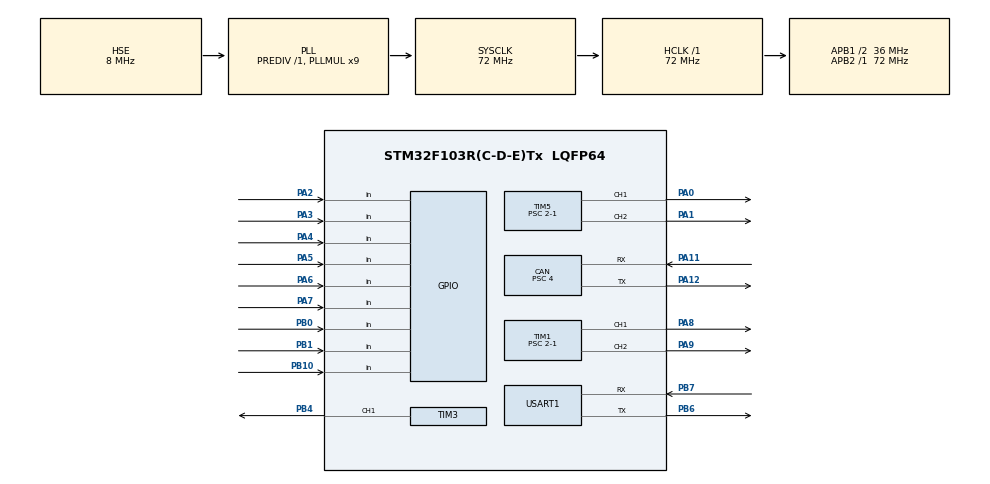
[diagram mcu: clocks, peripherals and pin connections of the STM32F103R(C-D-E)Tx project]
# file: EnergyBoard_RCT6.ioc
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CAN.AWUM=ENABLE
CAN.BS1=CAN_BS1_5TQ
CAN.BS2=CAN_BS2_3TQ
CAN.CalculateBaudRate=1000000
CAN.CalculateTimeBit=1000
CAN.CalculateTimeQuantum=111.11111111111111
CAN.Prescaler=4
CAN.TXFP=ENABLE
Dma.Request0=TIM1_CH1
Dma.Request1=TIM1_CH2
Dma.Request2=TIM3_CH1/TRIG
Dma.Request3=TIM5_CH1
Dma.Request4=TIM5_CH2
Dma.Request5=USART1_TX
Dma.TIM1_CH1.0.Direction=DMA_MEMORY_TO_PERIPH
Dma.TIM1_CH1.0.Instance=DMA1_Channel2
Dma.TIM1_CH1.0.MemDataAlignment=DMA_MDATAALIGN_HALFWORD
Dma.TIM1_CH1.0.MemInc=DMA_MINC_ENABLE
Dma.TIM1_CH1.0.Mode=DMA_NORMAL
Dma.TIM1_CH1.0.PeriphDataAlignment=DMA_PDATAALIGN_HALFWORD
Dma.TIM1_CH1.0.PeriphInc=DMA_PINC_DISABLE
Dma.TIM1_CH1.0.Priority=DMA_PRIORITY_LOW
Dma.TIM1_CH2.1.Direction=DMA_MEMORY_TO_PERIPH
Dma.TIM1_CH2.1.Instance=DMA1_Channel3
Dma.TIM1_CH2.1.MemDataAlignment=DMA_MDATAALIGN_HALFWORD
Dma.TIM1_CH2.1.MemInc=DMA_MINC_ENABLE
Dma.TIM1_CH2.1.Mode=DMA_NORMAL
Dma.TIM1_CH2.1.PeriphDataAlignment=DMA_PDATAALIGN_HALFWORD
Dma.TIM1_CH2.1.PeriphInc=DMA_PINC_DISABLE
Dma.TIM1_CH2.1.Priority=DMA_PRIORITY_LOW
Dma.TIM3_CH1/TRIG.2.Direction=DMA_MEMORY_TO_PERIPH
Dma.TIM3_CH1/TRIG.2.Instance=DMA1_Channel6
Dma.TIM3_CH1/TRIG.2.MemDataAlignment=DMA_MDATAALIGN_HALFWORD
Dma.TIM3_CH1/TRIG.2.MemInc=DMA_MINC_ENABLE
Dma.TIM3_CH1/TRIG.2.Mode=DMA_NORMAL
Dma.TIM3_CH1/TRIG.2.PeriphDataAlignment=DMA_PDATAALIGN_HALFWORD
Dma.TIM3_CH1/TRIG.2.PeriphInc=DMA_PINC_DISABLE
Dma.TIM3_CH1/TRIG.2.Priority=DMA_PRIORITY_LOW
Dma.TIM5_CH1.3.Direction=DMA_MEMORY_TO_PERIPH
Dma.TIM5_CH1.3.Instance=DMA2_Channel5
Dma.TIM5_CH1.3.MemDataAlignment=DMA_MDATAALIGN_HALFWORD
Dma.TIM5_CH1.3.MemInc=DMA_MINC_ENABLE
Dma.TIM5_CH1.3.Mode=DMA_NORMAL
Dma.TIM5_CH1.3.PeriphDataAlignment=DMA_PDATAALIGN_HALFWORD
Dma.TIM5_CH1.3.PeriphInc=DMA_PINC_DISABLE
Dma.TIM5_CH1.3.Priority=DMA_PRIORITY_LOW
Dma.TIM5_CH2.4.Direction=DMA_MEMORY_TO_PERIPH
Dma.TIM5_CH2.4.Instance=DMA2_Channel4
Dma.TIM5_CH2.4.MemDataAlignment=DMA_MDATAALIGN_HALFWORD
Dma.TIM5_CH2.4.MemInc=DMA_MINC_ENABLE
Dma.TIM5_CH2.4.Mode=DMA_NORMAL
Dma.TIM5_CH2.4.PeriphDataAlignment=DMA_PDATAALIGN_HALFWORD
Dma.TIM5_CH2.4.PeriphInc=DMA_PINC_DISABLE
Dma.TIM5_CH2.4.Priority=DMA_PRIORITY_LOW
Dma.USART1_TX.5.Direction=DMA_MEMORY_TO_PERIPH
Dma.USART1_TX.5.Instance=DMA1_Channel4
Dma.USART1_TX.5.MemDataAlignment=DMA_MDATAALIGN_BYTE
Dma.USART1_TX.5.MemInc=DMA_MINC_ENABLE
Dma.USART1_TX.5.Mode=DMA_NORMAL
Dma.USART1_TX.5.PeriphDataAlignment=DMA_PDATAALIGN_BYTE
Dma.USART1_TX.5.PeriphInc=DMA_PINC_DISABLE
Dma.USART1_TX.5.Priority=DMA_PRIORITY_LOW
Mcu.Family=STM32F1
Mcu.Name=STM32F103R(C-D-E)Tx
Mcu.Package=LQFP64
NVIC.CAN1_RX1_IRQn=true\:5\:0\:true\:false\:true\:true\:true\:true
NVIC.DMA1_Channel2_IRQn=true\:0\:0\:false\:false\:true\:false\:true\:true
NVIC.DMA1_Channel3_IRQn=true\:0\:0\:false\:false\:true\:false\:true\:true
NVIC.DMA1_Channel4_IRQn=true\:0\:0\:false\:false\:true\:false\:true\:true
NVIC.DMA1_Channel6_IRQn=true\:0\:0\:false\:false\:true\:false\:true\:true
NVIC.DMA2_Channel4_5_IRQn=true\:0\:0\:false\:false\:true\:false\:true\:true
NVIC.PriorityGroup=NVIC_PRIORITYGROUP_4
NVIC.USART1_IRQn=true\:0\:0\:false\:false\:true\:false\:true\:true
NVIC.USB_LP_CAN1_RX0_IRQn=true\:0\:0\:false\:false\:true\:true\:true\:true
PA0-WKUP.Signal=S_TIM5_CH1
PA1.Signal=S_TIM5_CH2
PA11.Mode=CAN_Activate
PA11.Signal=CAN_RX
PA12.Mode=CAN_Activate
PA12.Signal=CAN_TX
PA13.Mode=Serial_Wire
PA13.Signal=SYS_JTMS-SWDIO
PA14.Mode=Serial_Wire
PA14.Signal=SYS_JTCK-SWCLK
PA2.GPIO_PuPd=GPIO_PULLDOWN
PA2.Signal=GPIO_Input
PA3.GPIO_PuPd=GPIO_PULLDOWN
PA3.Signal=GPIO_Input
PA4.GPIO_PuPd=GPIO_PULLDOWN
PA4.Signal=GPIO_Input
PA5.GPIO_PuPd=GPIO_PULLDOWN
PA5.Signal=GPIO_Input
PA6.GPIO_PuPd=GPIO_PULLDOWN
PA6.Signal=GPIO_Input
PA7.GPIO_PuPd=GPIO_PULLDOWN
PA7.Signal=GPIO_Input
PA8.Signal=S_TIM1_CH1
PA9.Signal=S_TIM1_CH2
PB0.GPIO_PuPd=GPIO_PULLDOWN
PB0.Signal=GPIO_Input
PB1.GPIO_PuPd=GPIO_PULLDOWN
PB1.Signal=GPIO_Input
PB10.GPIO_PuPd=GPIO_PULLDOWN
PB10.Signal=GPIO_Input
PB4.Signal=S_TIM3_CH1
PB6.Mode=Asynchronous
PB6.Signal=USART1_TX
PB7.Mode=Asynchronous
PB7.Signal=USART1_RX
PD0-OSC_IN.Mode=HSE-External-Oscillator
PD0-OSC_IN.Signal=RCC_OSC_IN
PD1-OSC_OUT.Mode=HSE-External-Oscillator
PD1-OSC_OUT.Signal=RCC_OSC_OUT
ProjectManager.HeapSize=0x200
ProjectManager.StackSize=0x400
ProjectManager.TargetToolchain=CMake
RCC.AHBFreq_Value=72000000
RCC.APB1CLKDivider=RCC_HCLK_DIV2
RCC.APB1Freq_Value=36000000
RCC.APB1TimFreq_Value=72000000
RCC.APB2Freq_Value=72000000
RCC.APB2TimFreq_Value=72000000
RCC.HCLKFreq_Value=72000000
RCC.PLLMUL=RCC_PLL_MUL9
RCC.PLLSourceVirtual=RCC_PLLSOURCE_HSE
RCC.SYSCLKFreq_VALUE=72000000
RCC.SYSCLKSource=RCC_SYSCLKSOURCE_PLLCLK
RCC.USBFreq_Value=72000000
SH.S_TIM1_CH1.0=TIM1_CH1,PWM Generation1 CH1
SH.S_TIM1_CH2.0=TIM1_CH2,PWM Generation2 CH2
SH.S_TIM3_CH1.0=TIM3_CH1,PWM Generation1 CH1
SH.S_TIM5_CH1.0=TIM5_CH1,PWM Generation1 CH1
SH.S_TIM5_CH2.0=TIM5_CH2,PWM Generation2 CH2
TIM1.Channel-PWM\ Generation1\ CH1=TIM_CHANNEL_1
TIM1.Channel-PWM\ Generation2\ CH2=TIM_CHANNEL_2
TIM1.Period=45-1
TIM1.Prescaler=2-1
TIM3.Channel-PWM\ Generation1\ CH1=TIM_CHANNEL_1
TIM3.Period=45-1
TIM3.Prescaler=2-1
TIM5.Channel-PWM\ Generation1\ CH1=TIM_CHANNEL_1
TIM5.Channel-PWM\ Generation2\ CH2=TIM_CHANNEL_2
TIM5.Period=45-1
TIM5.Prescaler=2-1
USART1.VirtualMode=VM_ASYNC
board=custom

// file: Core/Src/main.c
/* USER CODE BEGIN Header */
/**
  ******************************************************************************
  * @file           : main.c
  * @brief          : Main program body
  ******************************************************************************
  * @attention
  *
  * Copyright (c) 2026 STMicroelectronics.
  * All rights reserved.
  *
  * This software is licensed under terms that can be found in the LICENSE file
  * in the root directory of this software component.
  * If no LICENSE file comes with this software, it is provided AS-IS.
  *
  ******************************************************************************
  */
/* USER CODE END Header */
#include "main.h"
#include "can.h"
#include "dma.h"
#include "tim.h"
#include "usart.h"
#include "gpio.h"

/* USER CODE BEGIN Includes */
#include <board.h>
/* USER CODE END Includes */

void SystemClock_Config(void);

int main(void)
{

  /* MCU Configuration--------------------------------------------------------*/

  /* Reset of all peripherals, Initializes the Flash interface and the Systick. */
  HAL_Init();

  /* Configure the system clock */
  SystemClock_Config();

  /* Initialize all configured peripherals */
  MX_GPIO_Init();
  MX_DMA_Init();
  MX_CAN_Init();
  MX_TIM1_Init();
  MX_TIM3_Init();
  MX_TIM5_Init();
  MX_USART1_UART_Init();

  /* Infinite loop */
  /* USER CODE BEGIN WHILE */
  Board_Init();
  while (1)
  {
    Board_Loop();
    /* USER CODE END WHILE */

  }
}

void SystemClock_Config(void)
{
  RCC_OscInitTypeDef RCC_OscInitStruct = {0};
  RCC_ClkInitTypeDef RCC_ClkInitStruct = {0};

  /** Initializes the RCC Oscillators according to the specified parameters
  * in the RCC_OscInitTypeDef structure.
  */
  RCC_OscInitStruct.OscillatorType = RCC_OSCILLATORTYPE_HSE;
  RCC_OscInitStruct.HSEState = RCC_HSE_ON;
  RCC_OscInitStruct.HSEPredivValue = RCC_HSE_PREDIV_DIV1;
  RCC_OscInitStruct.HSIState = RCC_HSI_ON;
  RCC_OscInitStruct.PLL.PLLState = RCC_PLL_ON;
  RCC_OscInitStruct.PLL.PLLSource = RCC_PLLSOURCE_HSE;
  RCC_OscInitStruct.PLL.PLLMUL = RCC_PLL_MUL9;
  if (HAL_RCC_OscConfig(&RCC_OscInitStruct) != HAL_OK)
  {
    Error_Handler();
  }

  /** Initializes the CPU, AHB and APB buses clocks
  */
  RCC_ClkInitStruct.ClockType = RCC_CLOCKTYPE_HCLK|RCC_CLOCKTYPE_SYSCLK
                              |RCC_CLOCKTYPE_PCLK1|RCC_CLOCKTYPE_PCLK2;
  RCC_ClkInitStruct.SYSCLKSource = RCC_SYSCLKSOURCE_PLLCLK;
  RCC_ClkInitStruct.AHBCLKDivider = RCC_SYSCLK_DIV1;
  RCC_ClkInitStruct.APB1CLKDivider = RCC_HCLK_DIV2;
  RCC_ClkInitStruct.APB2CLKDivider = RCC_HCLK_DIV1;

  if (HAL_RCC_ClockConfig(&RCC_ClkInitStruct, FLASH_LATENCY_2) != HAL_OK)
  {
    Error_Handler();
  }
}

void Error_Handler(void)
{
  __disable_irq();
  while (1)
  {
  }
}
